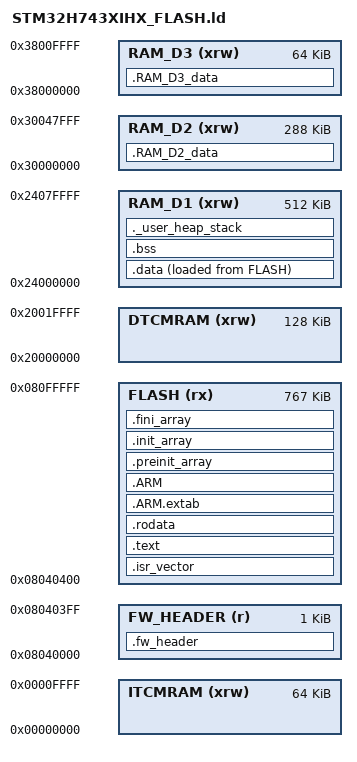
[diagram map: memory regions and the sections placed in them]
/*
******************************************************************************
**
**  File        : LinkerScript.ld
**
**  Author      : STM32CubeIDE
**
**  Abstract    : Linker script for STM32H7 series
**                2048Kbytes FLASH and 1056Kbytes RAM
**
**                Set heap size, stack size and stack location according
**                to application requirements.
**
**                Set memory bank area and size if external memory is used.
**
**  Target      : STMicroelectronics STM32
**
**  Distribution: The file is distributed as is, without any warranty
**                of any kind.
**
*****************************************************************************
** @attention
**
** Copyright (c) 2023 STMicroelectronics.
** All rights reserved.
**
** This software is licensed under terms that can be found in the LICENSE file
** in the root directory of this software component.
** If no LICENSE file comes with this software, it is provided AS-IS.
**
****************************************************************************
*/

/* Entry Point */
ENTRY(Reset_Handler)

/* Highest address of the user mode stack */
_estack = ORIGIN(RAM_D1) + LENGTH(RAM_D1);    /* end of RAM */
/* Generate a link error if heap and stack don't fit into RAM */
_Min_Heap_Size = 0x2000;      /* required amount of heap  */
_Min_Stack_Size = 0x2000; /* required amount of stack */

/* Specify the memory areas
 * [AS-IS] FLASH ORIGIN = 0x08000000, LENGTH = 2048K (standalone)
 * [TO-BE] FLASH ORIGIN = 0x08040400, LENGTH = 767K  (with AGR_BOOT V2)
 *
 * Flash Layout (AGR_BOOT V2):
 *   BL:          0x08000000 - 0x0803FFFF (256KB, Bank1 S0-S1)
 *   FW Header:   0x08040000 - 0x080403FF (1KB, AGR_FwInfo_t)
 *   App (here):  0x08040400 - 0x080FFFFF (767KB, Bank1 S2-S7 remainder)
 *   Backup:      0x08100000 - 0x081BFFFF (768KB, Bank2 S0-S5)
 *   Boot Config: 0x081C0000 - 0x081DFFFF (128KB, Bank2 S6)
 *   Reserved:    0x081E0000 - 0x081FFFFF (128KB, Bank2 S7)
 */
MEMORY
{
  FW_HEADER (r)  : ORIGIN = 0x08040000, LENGTH = 1K    /* AGR_FwInfo_t (64B) + padding (960B) */
  FLASH (rx)     : ORIGIN = 0x08040400, LENGTH = 767K
  DTCMRAM (xrw)  : ORIGIN = 0x20000000, LENGTH = 128K
  RAM_D1 (xrw)   : ORIGIN = 0x24000000, LENGTH = 512K
  RAM_D2 (xrw)   : ORIGIN = 0x30000000, LENGTH = 288K
  RAM_D3 (xrw)   : ORIGIN = 0x38000000, LENGTH = 64K
  ITCMRAM (xrw)  : ORIGIN = 0x00000000, LENGTH = 64K
}

/* Define output sections */
SECTIONS
{
  /* AGR_BOOT V2: FW Info header at Active Slot base (0x08040000).
   * Placed BEFORE .isr_vector so SWD flash includes it in the same erase/write.
   * BL reads this to validate App before jumping. */
  .fw_header :
  {
    . = ALIGN(4);
    KEEP(*(.fw_header))
    . = ALIGN(4);
  } >FW_HEADER

  /* The startup code goes first into FLASH */
  .isr_vector :
  {
    . = ALIGN(4);
    KEEP(*(.isr_vector)) /* Startup code */
    . = ALIGN(4);
  } >FLASH

  /* The program code and other data goes into FLASH */
  .text :
  {
    . = ALIGN(4);
    *(.text)           /* .text sections (code) */
    *(.text*)          /* .text* sections (code) */
    *(.glue_7)         /* glue arm to thumb code */
    *(.glue_7t)        /* glue thumb to arm code */
    *(.eh_frame)

    KEEP (*(.init))
    KEEP (*(.fini))

    . = ALIGN(4);
    _etext = .;        /* define a global symbols at end of code */
  } >FLASH

  /* Constant data goes into FLASH */
  .rodata :
  {
    . = ALIGN(4);
    *(.rodata)         /* .rodata sections (constants, strings, etc.) */
    *(.rodata*)        /* .rodata* sections (constants, strings, etc.) */
    . = ALIGN(4);
  } >FLASH

  .ARM.extab   : { *(.ARM.extab* .gnu.linkonce.armextab.*) } >FLASH
  .ARM : {
    __exidx_start = .;
    *(.ARM.exidx*)
    __exidx_end = .;
  } >FLASH

  .preinit_array     :
  {
    PROVIDE_HIDDEN (__preinit_array_start = .);
    KEEP (*(.preinit_array*))
    PROVIDE_HIDDEN (__preinit_array_end = .);
  } >FLASH

  .init_array :
  {
    PROVIDE_HIDDEN (__init_array_start = .);
    KEEP (*(SORT(.init_array.*)))
    KEEP (*(.init_array*))
    PROVIDE_HIDDEN (__init_array_end = .);
  } >FLASH

  .fini_array :
  {
    PROVIDE_HIDDEN (__fini_array_start = .);
    KEEP (*(SORT(.fini_array.*)))
    KEEP (*(.fini_array*))
    PROVIDE_HIDDEN (__fini_array_end = .);
  } >FLASH

  /* used by the startup to initialize data */
  _sidata = LOADADDR(.data);

  /* Initialized data sections goes into RAM, load LMA copy after code */
  .data :
  {
    . = ALIGN(4);
    _sdata = .;        /* create a global symbol at data start */
    *(.data)           /* .data sections */
    *(.data*)          /* .data* sections */
    *(.RamFunc)        /* .RamFunc sections */
    *(.RamFunc*)       /* .RamFunc* sections */

    . = ALIGN(4);
    _edata = .;        /* define a global symbol at data end */
  } >RAM_D1 AT> FLASH

  /* Uninitialized data section */
  . = ALIGN(4);
  .bss :
  {
    /* This is used by the startup in order to initialize the .bss section */
    _sbss = .;         /* define a global symbol at bss start */
    __bss_start__ = _sbss;
    *(.bss)
    *(.bss*)
    *(COMMON)

    . = ALIGN(4);
    _ebss = .;         /* define a global symbol at bss end */
    __bss_end__ = _ebss;
  } >RAM_D1

  /* [???] D2, D3 ???? ???? ??? (???? .bss ????) */
  .RAM_D2_data (NOLOAD) :
  {
    . = ALIGN(4);
    *(.RAM_D2_data)
    *(.RAM_D2_data*)
    . = ALIGN(4);
  } > RAM_D2

  .RAM_D3_data (NOLOAD) :
  {
    . = ALIGN(4);
    *(.RAM_D3_data)
    *(.RAM_D3_data*)
    . = ALIGN(4);
  } > RAM_D3

  /* User_heap_stack section, used to check that there is enough RAM left */
  ._user_heap_stack :
  {
    . = ALIGN(8);
    PROVIDE ( end = . );
    PROVIDE ( _end = . );
    . = . + _Min_Heap_Size;
    . = . + _Min_Stack_Size;
    . = ALIGN(8);
  } >RAM_D1

  /* Remove information from the standard libraries */
  /DISCARD/ :
  {
    libc.a ( * )
    libm.a ( * )
    libgcc.a ( * )
  }

  .ARM.attributes 0 : { *(.ARM.attributes) }
}


